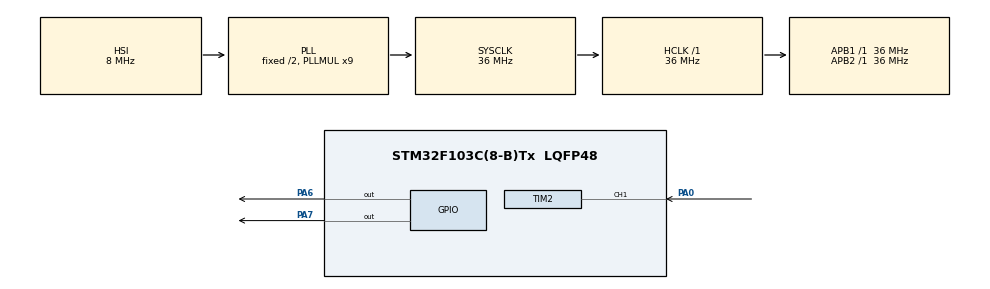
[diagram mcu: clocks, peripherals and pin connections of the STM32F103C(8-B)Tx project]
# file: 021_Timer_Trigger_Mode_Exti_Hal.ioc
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Mcu.Family=STM32F1
Mcu.Name=STM32F103C(8-B)Tx
Mcu.Package=LQFP48
NVIC.PriorityGroup=NVIC_PRIORITYGROUP_4
NVIC.TIM2_IRQn=true\:0\:0\:false\:false\:true\:true\:true\:true
PA0-WKUP.Signal=S_TIM2_CH1_ETR
PA13.Mode=Serial_Wire
PA13.Signal=SYS_JTMS-SWDIO
PA14.Mode=Serial_Wire
PA14.Signal=SYS_JTCK-SWCLK
PA6.Signal=GPIO_Output
PA7.Signal=GPIO_Output
ProjectManager.HeapSize=0x200
ProjectManager.StackSize=0x400
ProjectManager.TargetToolchain=STM32CubeIDE
RCC.AHBFreq_Value=36000000
RCC.APB1Freq_Value=36000000
RCC.APB1TimFreq_Value=36000000
RCC.APB2Freq_Value=36000000
RCC.APB2TimFreq_Value=36000000
RCC.HCLKFreq_Value=36000000
RCC.PLLMUL=RCC_PLL_MUL9
RCC.SYSCLKFreq_VALUE=36000000
RCC.SYSCLKSource=RCC_SYSCLKSOURCE_PLLCLK
RCC.USBFreq_Value=36000000
SH.S_TIM2_CH1_ETR.0=TIM2_CH1,TriggerSource_TI1FP1
TIM2.Period=999
TIM2.Prescaler=35999
TIM2.Slave_TriggerFilter=15
VP_TIM2_VS_ClockSourceINT.Mode=Internal
VP_TIM2_VS_ControllerModeTrigger.Mode=Trigger Mode
board=custom

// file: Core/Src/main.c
/* USER CODE BEGIN Header */
/**
  ******************************************************************************
  * @file           : main.c
  * @brief          : Main program body
  ******************************************************************************
  * @attention
  *
  * Copyright (c) 2024 STMicroelectronics.
  * All rights reserved.
  *
  * This software is licensed under terms that can be found in the LICENSE file
  * in the root directory of this software component.
  * If no LICENSE file comes with this software, it is provided AS-IS.
  *
  ******************************************************************************
  */
/* USER CODE END Header */
#include "main.h"

TIM_HandleTypeDef htim2;

/* USER CODE BEGIN PV */
uint16_t count;
/* USER CODE END PV */

void SystemClock_Config(void);
static void MX_GPIO_Init(void);
static void MX_TIM2_Init(void);

/* USER CODE BEGIN 0 */
void HAL_TIM_PeriodElapsedCallback(TIM_HandleTypeDef *htim){
	if(htim->Instance == TIM2)
		HAL_GPIO_TogglePin(GPIOA, GPIO_PIN_6);
}

/* USER CODE END 0 */

int main(void)
{

  /* MCU Configuration--------------------------------------------------------*/

  /* Reset of all peripherals, Initializes the Flash interface and the Systick. */
  HAL_Init();

  /* Configure the system clock */
  SystemClock_Config();

  /* Initialize all configured peripherals */
  MX_GPIO_Init();
  MX_TIM2_Init();
  /* USER CODE BEGIN 2 */
  __HAL_TIM_CLEAR_FLAG(&htim2, TIM_FLAG_UPDATE);

  /* USER CODE END 2 */

  /* Infinite loop */
  while (1)
  {

    /* USER CODE BEGIN 3 */
	  count = __HAL_TIM_GET_COUNTER(&htim2);

	  if(__HAL_TIM_GET_FLAG(&htim2, TIM_FLAG_TRIGGER)){					//	ENTER WHEN FLAG RAİSED

		  HAL_GPIO_TogglePin(GPIOA, GPIO_PIN_7);						// LED BLİNK AS FLAG RAİSE

		  __HAL_TIM_ENABLE_IT(&htim2, TIM_FLAG_UPDATE);					// ENTER İNTERRUPT

		  __HAL_TIM_CLEAR_FLAG(&htim2,TIM_FLAG_TRIGGER);				//CLEAR FLAG TO REUSE

	  }

  }
  /* USER CODE END 3 */
}

void SystemClock_Config(void)
{
  RCC_OscInitTypeDef RCC_OscInitStruct = {0};
  RCC_ClkInitTypeDef RCC_ClkInitStruct = {0};

  /** Initializes the RCC Oscillators according to the specified parameters
  * in the RCC_OscInitTypeDef structure.
  */
  RCC_OscInitStruct.OscillatorType = RCC_OSCILLATORTYPE_HSI;
  RCC_OscInitStruct.HSIState = RCC_HSI_ON;
  RCC_OscInitStruct.HSICalibrationValue = RCC_HSICALIBRATION_DEFAULT;
  RCC_OscInitStruct.PLL.PLLState = RCC_PLL_ON;
  RCC_OscInitStruct.PLL.PLLSource = RCC_PLLSOURCE_HSI_DIV2;
  RCC_OscInitStruct.PLL.PLLMUL = RCC_PLL_MUL9;
  if (HAL_RCC_OscConfig(&RCC_OscInitStruct) != HAL_OK)
  {
    Error_Handler();
  }

  /** Initializes the CPU, AHB and APB buses clocks
  */
  RCC_ClkInitStruct.ClockType = RCC_CLOCKTYPE_HCLK|RCC_CLOCKTYPE_SYSCLK
                              |RCC_CLOCKTYPE_PCLK1|RCC_CLOCKTYPE_PCLK2;
  RCC_ClkInitStruct.SYSCLKSource = RCC_SYSCLKSOURCE_PLLCLK;
  RCC_ClkInitStruct.AHBCLKDivider = RCC_SYSCLK_DIV1;
  RCC_ClkInitStruct.APB1CLKDivider = RCC_HCLK_DIV1;
  RCC_ClkInitStruct.APB2CLKDivider = RCC_HCLK_DIV1;

  if (HAL_RCC_ClockConfig(&RCC_ClkInitStruct, FLASH_LATENCY_1) != HAL_OK)
  {
    Error_Handler();
  }
}

static void MX_TIM2_Init(void)
{

  TIM_ClockConfigTypeDef sClockSourceConfig = {0};
  TIM_SlaveConfigTypeDef sSlaveConfig = {0};
  TIM_MasterConfigTypeDef sMasterConfig = {0};

  htim2.Instance = TIM2;
  htim2.Init.Prescaler = 35999;
  htim2.Init.CounterMode = TIM_COUNTERMODE_UP;
  htim2.Init.Period = 999;
  htim2.Init.ClockDivision = TIM_CLOCKDIVISION_DIV1;
  htim2.Init.AutoReloadPreload = TIM_AUTORELOAD_PRELOAD_DISABLE;
  if (HAL_TIM_Base_Init(&htim2) != HAL_OK)
  {
    Error_Handler();
  }
  sClockSourceConfig.ClockSource = TIM_CLOCKSOURCE_INTERNAL;
  if (HAL_TIM_ConfigClockSource(&htim2, &sClockSourceConfig) != HAL_OK)
  {
    Error_Handler();
  }
  sSlaveConfig.SlaveMode = TIM_SLAVEMODE_TRIGGER;
  sSlaveConfig.InputTrigger = TIM_TS_TI1FP1;
  sSlaveConfig.TriggerPolarity = TIM_TRIGGERPOLARITY_RISING;
  sSlaveConfig.TriggerFilter = 15;
  if (HAL_TIM_SlaveConfigSynchro(&htim2, &sSlaveConfig) != HAL_OK)
  {
    Error_Handler();
  }
  sMasterConfig.MasterOutputTrigger = TIM_TRGO_RESET;
  sMasterConfig.MasterSlaveMode = TIM_MASTERSLAVEMODE_DISABLE;
  if (HAL_TIMEx_MasterConfigSynchronization(&htim2, &sMasterConfig) != HAL_OK)
  {
    Error_Handler();
  }

}

static void MX_GPIO_Init(void)
{
  GPIO_InitTypeDef GPIO_InitStruct = {0};

  /* GPIO Ports Clock Enable */
  __HAL_RCC_GPIOA_CLK_ENABLE();

  /*Configure GPIO pin Output Level */
  HAL_GPIO_WritePin(GPIOA, GPIO_PIN_6|GPIO_PIN_7, GPIO_PIN_RESET);

  /*Configure GPIO pins : PA6 PA7 */
  GPIO_InitStruct.Pin = GPIO_PIN_6|GPIO_PIN_7;
  GPIO_InitStruct.Mode = GPIO_MODE_OUTPUT_PP;
  GPIO_InitStruct.Pull = GPIO_NOPULL;
  GPIO_InitStruct.Speed = GPIO_SPEED_FREQ_LOW;
  HAL_GPIO_Init(GPIOA, &GPIO_InitStruct);

}

void Error_Handler(void)
{
  __disable_irq();
  while (1)
  {
  }
}
